# ATSAML11E14A device description
Architecture: CORTEX-M23; Family: SAML; Series: SAML11
Registers are 32-bit, read-write, reset 0x0 unless marked. A register's access mark holds for its fields unless they carry their own. Offsets are from the block's base; [hi:lo] are bit positions; 'fields as' and 'values as' point back to an identical list.

## TRNG — True Random Generator
Instances: TRNG 0x42002800
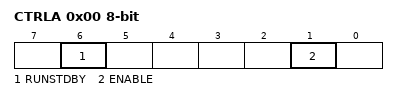
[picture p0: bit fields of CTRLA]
0x00 CTRLA 8-bit — Control A
  [6] RUNSTDBY — Run in Standby
  [1] ENABLE
0x04 EVCTRL 8-bit — Event Control
  [0] DATARDYEO — Data Ready Event Output
0x08 INTENCLR 8-bit (atomic clear) — Interrupt Enable Clear
  [0] DATARDY — Data Ready Interrupt Enable
0x09 INTENSET 8-bit (atomic set) — Interrupt Enable Set
  [0] DATARDY — Data Ready Interrupt Enable
0x0A INTFLAG 8-bit (atomic clear) — Interrupt Flag Status and Clear
  [0] DATARDY — Data Ready Interrupt Flag
0x20 DATA ro — Output Data

## WDT — Watchdog Timer
Instances: WDT 0x40002000
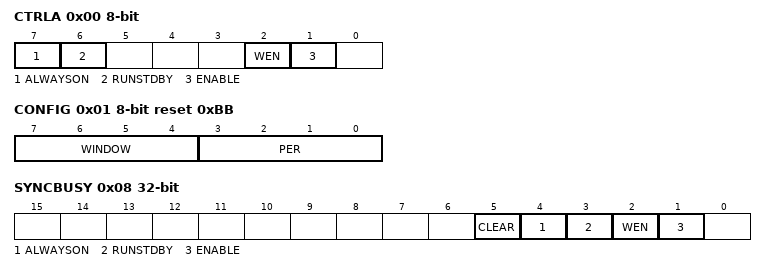
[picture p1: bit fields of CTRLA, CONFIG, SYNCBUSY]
0x00 CTRLA 8-bit (WSYNC) — Control
  [7] ALWAYSON
  [6] RUNSTDBY — Run During Standby
  [2] WEN — Watchdog Timer Window Mode Enable
  [1] ENABLE
0x01 CONFIG 8-bit reset 0xBB — Configuration
  [7:4] WINDOW — Window Mode Time-Out Period
    0=CYC8 (8 clock cycles); 1=CYC16 (16 clock cycles); 2=CYC32 (32 clock cycles); 3=CYC64 (64 clock cycles); 4=CYC128 (128 clock cycles); 5=CYC256 (256 clock cycles); 6=CYC512 (512 clock cycles); 7=CYC1024 (1024 clock cycles); 8=CYC2048 (2048 clock cycles); 9=CYC4096 (4096 clock cycles); 10=CYC8192 (8192 clock cycles); 11=CYC16384 (16384 clock cycles)
  [3:0] PER — Time-Out Period
    values as WINDOW
0x02 EWCTRL 8-bit reset 0xB — Early Warning Interrupt Control
  [3:0] EWOFFSET — Early Warning Interrupt Time Offset
    0=CYC8 (8 clock cycles); 1=CYC16 (16 clock cycles); 2=CYC32 (32 clock cycles); 3=CYC64 (64 clock cycles); 4=CYC128 (128 clock cycles); 5=CYC256 (256 clock cycles); 6=CYC512 (512 clock cycles); 7=CYC1024 (1024 clock cycles); 8=CYC2048 (2048 clock cycles); 9=CYC4096 (4096 clock cycles); 10=CYC8192 (8192 clock cycles)
0x04 INTENCLR 8-bit (atomic clear) — Interrupt Enable Clear
  [0] EW — Early Warning Interrupt Enable
0x05 INTENSET 8-bit (atomic set) — Interrupt Enable Set
  [0] EW — Early Warning Interrupt Enable
0x06 INTFLAG 8-bit (atomic clear) — Interrupt Flag Status and Clear
  [0] EW — Early Warning
0x08 SYNCBUSY ro — Synchronization Busy
  [5] CLEAR — Clear Synchronization Busy
  [4] ALWAYSON — Always-On Synchronization Busy
  [3] RUNSTDBY — Run During Standby Synchronization Busy
  [2] WEN — Window Enable Synchronization Busy
  [1] ENABLE — Enable Synchronization Busy
0x0C CLEAR 8-bit wo (WSYNC)
  [7:0] CLEAR — Watchdog Clear
    165=KEY (Clear Key)

## CoreDebug — Debug Control Block
Instances: CoreDebug 0xE000EDF0, CoreDebug_NS 0xE002EDF0
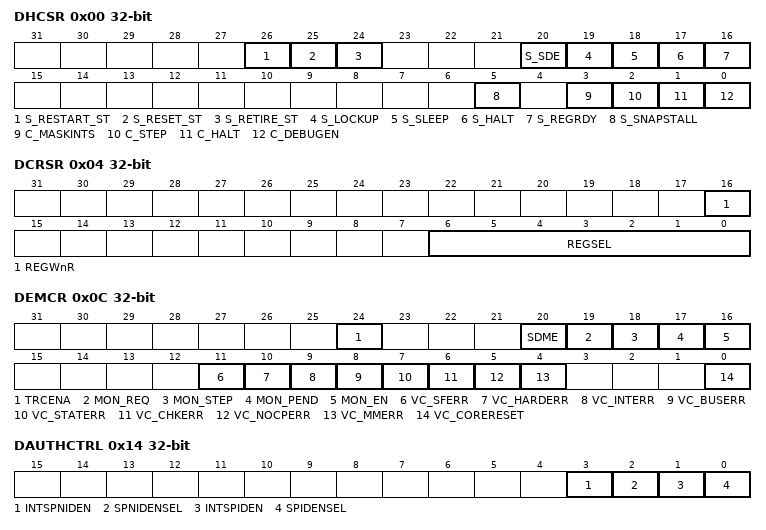
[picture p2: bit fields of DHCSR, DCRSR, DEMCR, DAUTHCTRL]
0x00 DHCSR reset not defined — Debug Halting Control and Status Register
  [26] S_RESTART_ST — Restart sticky status
  [25] S_RESET_ST — Reset sticky status
  [24] S_RETIRE_ST — Retire sticky status
  [20] S_SDE — Secure debug enabled
  [19] S_LOCKUP — Lockup status
  [18] S_SLEEP — Sleeping status
  [17] S_HALT — Halted status
  [16] S_REGRDY — Register ready status
  [5] S_SNAPSTALL — Snap stall control
  [3] C_MASKINTS — Mask PendSV, SysTick and external configurable interrupts
  [2] C_STEP — Enable single step
  [1] C_HALT — Halt processor
  [0] C_DEBUGEN — Enable Halting debug
0x04 DCRSR wo reset not defined — Debug Core Register Select Register
  [16] REGWnR — Register write/not-read access
  [6:0] REGSEL — Register selector
0x0C DEMCR reset not defined — Debug Exception and Monitor Control Register
  [24] TRCENA — Global DWT and ITM features enable
  [20] SDME — Secure DebugMonitor enable
  [19] MON_REQ — DebugMonitor semaphore bit
  [18] MON_STEP — Enable DebugMonitor stepping
  [17] MON_PEND — DebugMonitor pending state
  [16] MON_EN — DebugMonitor enable
  [11] VC_SFERR — SecureFault exception Halting debug vector catch enable
  [10] VC_HARDERR — HardFault exception Halting debug vector catch enable
  [9] VC_INTERR — Excception entry and return faults Halting debug vector catch enable
  [8] VC_BUSERR — BusFault exception Halting debug vector catch enable
  [7] VC_STATERR — UsageFault exception state information error Halting debug vector catch enable
  [6] VC_CHKERR — UsageFault exception checking error Halting debug vector catch enable
  [5] VC_NOCPERR — UsageFault exception coprocessor access Halting debug vector catch enable
  [4] VC_MMERR — MemManage exception Halting debug vector catch enable
  [0] VC_CORERESET — Core reset Halting debug vector catch enable
0x14 DAUTHCTRL reset not defined — Debug Authentication Control Register
  [3] INTSPNIDEN — Internal Secure non-invasive debug enable
  [2] SPNIDENSEL — Secure non-invasive debug enable select
  [1] INTSPIDEN — Internal Secure invasive debug enable
  [0] SPIDENSEL — Secure invasive debug enable select
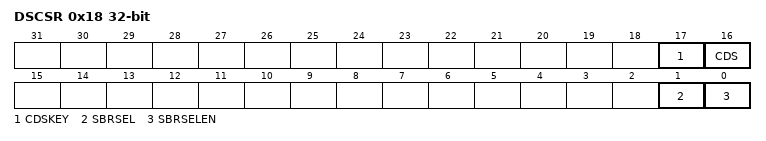
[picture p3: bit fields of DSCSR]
0x18 DSCSR reset not defined — Debug Security Control and Status Register
  [17] CDSKEY — CDS field write-enable key
  [16] CDS — Current domain Secure
  [1] SBRSEL — Secure Banked register select
  [0] SBRSELEN — Secure Banked register select enable

## Notices in the file
Copyright (c) 2019 Microchip Technology Inc.
SPDX-License-Identifier: Apache-2.0
Licensed under the Apache License, Version 2.0 (the "License");
you may not use this file except in compliance with the License.
You may obtain a copy of the License at
http://www.apache.org/licenses/LICENSE-2.0
Unless required by applicable law or agreed to in writing, software
distributed under the License is distributed on an "AS IS" BASIS,
WITHOUT WARRANTIES OR CONDITIONS OF ANY KIND, either express or implied.
See the License for the specific language governing permissions and
limitations under the License.
